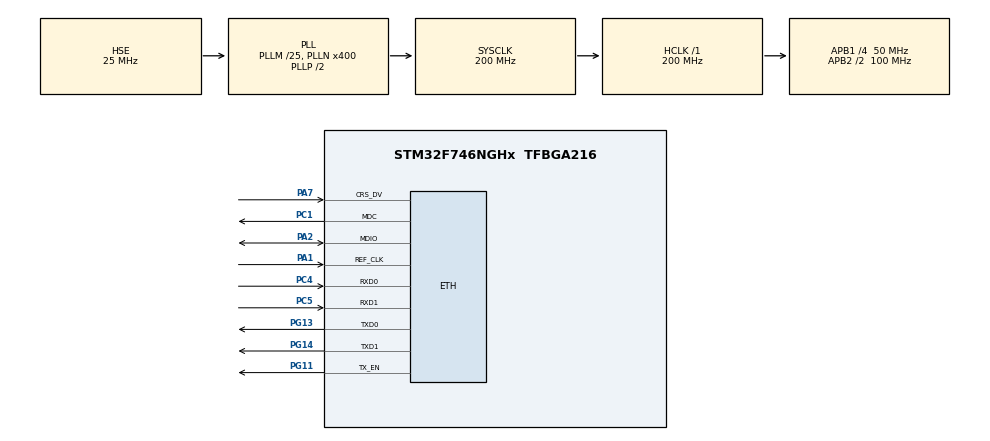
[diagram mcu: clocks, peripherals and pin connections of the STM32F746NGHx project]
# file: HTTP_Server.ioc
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ETH.MediaInterface=HAL_ETH_RMII_MODE
LWIP.BSP.number=1
LWIP.GATEWAY_ADDRESS=010.004.090.001
LWIP.IP_ADDRESS=010.004.090.111
LWIP.LWIP_DHCP=0
LWIP.LWIP_HTTPD=1
LWIP.MEM_SIZE=10*1024
LWIP.NETMASK_ADDRESS=255.255.255.000
LWIP.Version=v2.1.2_Cube
LWIP0.BSP.STBoard=false
LWIP0.BSP.api=BSP_COMPONENT_DRIVER
LWIP0.BSP.component=LAN8742
LWIP0.BSP.instance=LAN8742
LWIP0.BSP.name=Driver_PHY
LWIP0.BSP.semaphore=S_LAN8742
LWIP0.BSP.solution=LAN8742
Mcu.Family=STM32F7
Mcu.Name=STM32F746NGHx
Mcu.Package=TFBGA216
NVIC.PriorityGroup=NVIC_PRIORITYGROUP_4
PA1.Mode=RMII
PA1.Signal=ETH_REF_CLK
PA2.Mode=RMII
PA2.Signal=ETH_MDIO
PA7.Mode=RMII
PA7.Signal=ETH_CRS_DV
PC1.Mode=RMII
PC1.Signal=ETH_MDC
PC4.Mode=RMII
PC4.Signal=ETH_RXD0
PC5.Mode=RMII
PC5.Signal=ETH_RXD1
PG11.Mode=RMII
PG11.Signal=ETH_TX_EN
PG13.Mode=RMII
PG13.Signal=ETH_TXD0
PG14.Mode=RMII
PG14.Signal=ETH_TXD1
PH0/OSC_IN.Mode=HSE-External-Oscillator
PH0/OSC_IN.Signal=RCC_OSC_IN
PH1/OSC_OUT.Mode=HSE-External-Oscillator
PH1/OSC_OUT.Signal=RCC_OSC_OUT
ProjectManager.HeapSize=0x200
ProjectManager.StackSize=0x400
ProjectManager.TargetToolchain=STM32CubeIDE
RCC.AHBFreq_Value=200000000
RCC.APB1CLKDivider=RCC_HCLK_DIV4
RCC.APB1Freq_Value=50000000
RCC.APB1TimFreq_Value=100000000
RCC.APB2CLKDivider=RCC_HCLK_DIV2
RCC.APB2Freq_Value=100000000
RCC.APB2TimFreq_Value=200000000
RCC.CortexFreq_Value=200000000
RCC.HCLKFreq_Value=200000000
RCC.HSE_VALUE=25000000
RCC.HSI_VALUE=16000000
RCC.PLL48CLockSelection=RCC_CLK48SOURCE_PLLSAIP
RCC.PLLI2SN=100
RCC.PLLM=25
RCC.PLLN=400
RCC.PLLQ=9
RCC.PLLSAIN=384
RCC.PLLSAIP=RCC_PLLSAIP_DIV8
RCC.PLLSAIR=5
RCC.PLLSAIRDiv=RCC_PLLSAIDIVR_8
RCC.PLLSourceVirtual=RCC_PLLSOURCE_HSE
RCC.SDMMCClockSelection=RCC_SDMMC1CLKSOURCE_CLK48
RCC.SYSCLKFreq_VALUE=200000000
RCC.SYSCLKSource=RCC_SYSCLKSOURCE_PLLCLK
RCC.USBFreq_Value=48000000
RCC.VCOOutputFreq_Value=400000000
VP_LWIP_VS_Enabled.Mode=Enabled
board=STM32F746G-DISCO

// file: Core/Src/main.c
/* USER CODE BEGIN Header */
/**
  ******************************************************************************
  * @file           : main.c
  * @brief          : Main program body
  ******************************************************************************
  * @attention
  *
  * Copyright (c) 2026 STMicroelectronics.
  * All rights reserved.
  *
  * This software is licensed under terms that can be found in the LICENSE file
  * in the root directory of this software component.
  * If no LICENSE file comes with this software, it is provided AS-IS.
  *
  ******************************************************************************
  */
/* USER CODE END Header */
#include "main.h"
#include "lwip.h"

/* USER CODE BEGIN Includes */
#include "lwip/apps/httpd.h"
/*
 * https://www.youtube.com/watch?v=l7pDTva5IMQ
 * Middlewares>Third_Party>LwIP>apps>http added fsdata.c and fsdata_custom.c, also removed these files from build
 * How to convert .html files to .c file: in terminal: perl makefsdata.pl
 * How is data dumped onto ethernet?
 * */
/* USER CODE END Includes */

void SystemClock_Config(void);
static void MX_GPIO_Init(void);
/* USER CODE BEGIN PFP */
extern struct netif gnetif;
/* USER CODE END PFP */

int main(void)
{

  /* MCU Configuration--------------------------------------------------------*/

  /* Reset of all peripherals, Initializes the Flash interface and the Systick. */
  HAL_Init();

  /* Configure the system clock */
  SystemClock_Config();

  /* Initialize all configured peripherals */
  MX_GPIO_Init();
  MX_LWIP_Init();
  /* USER CODE BEGIN 2 */
	httpd_init();
  /* USER CODE END 2 */

  /* Infinite loop */
  while (1)
  {

    /* USER CODE BEGIN 3 */
	  MX_LWIP_Process();
	  ethernetif_input(&gnetif);
	  sys_check_timeouts();
	  static uint32_t link_timer = 0;
		  if (HAL_GetTick() - link_timer >= 100)
		  {
			  link_timer = HAL_GetTick();
			  ethernet_link_check_state(&gnetif);
		  }
	}
  /* USER CODE END 3 */
}

void SystemClock_Config(void)
{
  RCC_OscInitTypeDef RCC_OscInitStruct = {0};
  RCC_ClkInitTypeDef RCC_ClkInitStruct = {0};

  /** Configure the main internal regulator output voltage
  */
  __HAL_RCC_PWR_CLK_ENABLE();
  __HAL_PWR_VOLTAGESCALING_CONFIG(PWR_REGULATOR_VOLTAGE_SCALE1);

  /** Initializes the RCC Oscillators according to the specified parameters
  * in the RCC_OscInitTypeDef structure.
  */
  RCC_OscInitStruct.OscillatorType = RCC_OSCILLATORTYPE_HSE;
  RCC_OscInitStruct.HSEState = RCC_HSE_ON;
  RCC_OscInitStruct.PLL.PLLState = RCC_PLL_ON;
  RCC_OscInitStruct.PLL.PLLSource = RCC_PLLSOURCE_HSE;
  RCC_OscInitStruct.PLL.PLLM = 25;
  RCC_OscInitStruct.PLL.PLLN = 400;
  RCC_OscInitStruct.PLL.PLLP = RCC_PLLP_DIV2;
  RCC_OscInitStruct.PLL.PLLQ = 9;
  if (HAL_RCC_OscConfig(&RCC_OscInitStruct) != HAL_OK)
  {
    Error_Handler();
  }

  /** Activate the Over-Drive mode
  */
  if (HAL_PWREx_EnableOverDrive() != HAL_OK)
  {
    Error_Handler();
  }

  /** Initializes the CPU, AHB and APB buses clocks
  */
  RCC_ClkInitStruct.ClockType = RCC_CLOCKTYPE_HCLK|RCC_CLOCKTYPE_SYSCLK
                              |RCC_CLOCKTYPE_PCLK1|RCC_CLOCKTYPE_PCLK2;
  RCC_ClkInitStruct.SYSCLKSource = RCC_SYSCLKSOURCE_PLLCLK;
  RCC_ClkInitStruct.AHBCLKDivider = RCC_SYSCLK_DIV1;
  RCC_ClkInitStruct.APB1CLKDivider = RCC_HCLK_DIV4;
  RCC_ClkInitStruct.APB2CLKDivider = RCC_HCLK_DIV2;

  if (HAL_RCC_ClockConfig(&RCC_ClkInitStruct, FLASH_LATENCY_6) != HAL_OK)
  {
    Error_Handler();
  }
}

static void MX_GPIO_Init(void)
{

  /* GPIO Ports Clock Enable */
  __HAL_RCC_GPIOG_CLK_ENABLE();
  __HAL_RCC_GPIOH_CLK_ENABLE();
  __HAL_RCC_GPIOC_CLK_ENABLE();
  __HAL_RCC_GPIOA_CLK_ENABLE();

}

void Error_Handler(void)
{
  __disable_irq();
  while (1)
  {
  }
}
